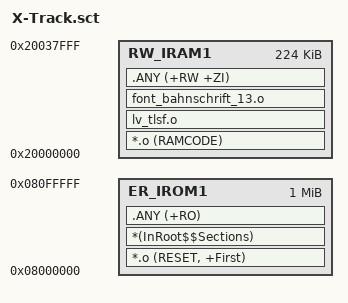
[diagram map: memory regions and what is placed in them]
; *************************************************************
; *** Scatter-Loading Description File generated by uVision ***
; *************************************************************

LR_IROM1 0x08000000 0x00100000  {    ; load region size_region
  ER_IROM1 0x08000000 0x00100000  {  ; load address = execution address
   *.o (RESET, +First)
   *(InRoot$$Sections)
   .ANY (+RO)
  }
  RW_IRAM1 0x20000000 0x00038000  {  ; RW data
   *.o (RAMCODE)
   lv_tlsf.o
   font_bahnschrift_13.o
   .ANY (+RW +ZI)
  }
}
